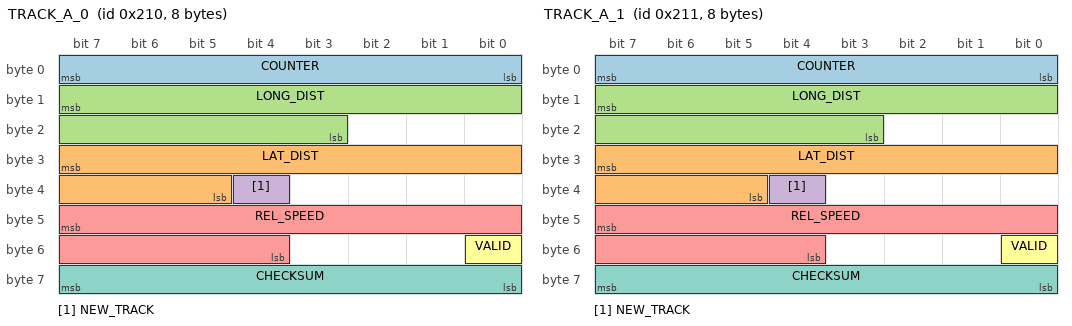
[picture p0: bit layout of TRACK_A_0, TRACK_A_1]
BO_ 528 TRACK_A_0: 8 XXX
 SG_ COUNTER : 7|8@0+ (1,0) [0|255] "" XXX
 SG_ LAT_DIST : 31|11@0- (0.04,0) [-50|50] "m" XXX
 SG_ LONG_DIST : 15|13@0+ (0.04,0) [0|300] "m" XXX
 SG_ NEW_TRACK : 36|1@0+ (1,0) [0|1] "" XXX
 SG_ REL_SPEED : 47|12@0- (0.025,0) [-100|100] "m/s" XXX
 SG_ VALID : 48|1@0+ (1,0) [0|1] "" XXX
 SG_ CHECKSUM : 63|8@0+ (1,0) [0|255] "" XXX

BO_ 529 TRACK_A_1: 8 XXX
 SG_ COUNTER : 7|8@0+ (1,0) [0|255] "" XXX
 SG_ LAT_DIST : 31|11@0- (0.04,0) [-50|50] "m" XXX
 SG_ LONG_DIST : 15|13@0+ (0.04,0) [0|300] "m" XXX
 SG_ NEW_TRACK : 36|1@0+ (1,0) [0|1] "" XXX
 SG_ REL_SPEED : 47|12@0- (0.025,0) [-100|100] "m/s" XXX
 SG_ VALID : 48|1@0+ (1,0) [0|1] "" XXX
 SG_ CHECKSUM : 63|8@0+ (1,0) [0|255] "" XXX

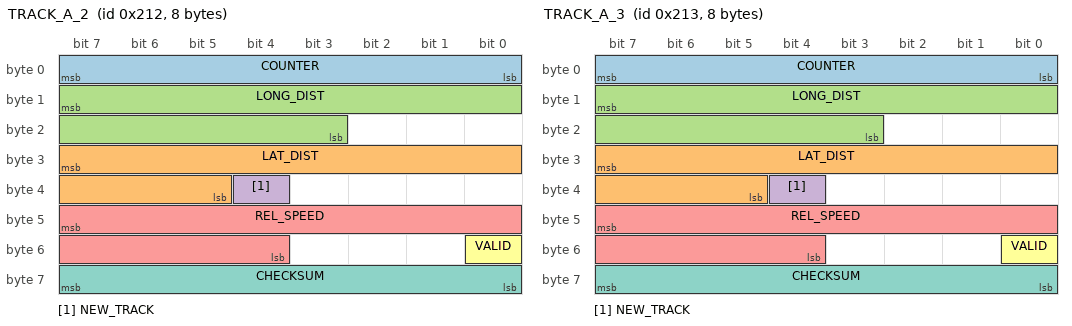
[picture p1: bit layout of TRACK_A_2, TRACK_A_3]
BO_ 530 TRACK_A_2: 8 XXX
 SG_ COUNTER : 7|8@0+ (1,0) [0|255] "" XXX
 SG_ LAT_DIST : 31|11@0- (0.04,0) [-50|50] "m" XXX
 SG_ LONG_DIST : 15|13@0+ (0.04,0) [0|300] "m" XXX
 SG_ NEW_TRACK : 36|1@0+ (1,0) [0|1] "" XXX
 SG_ REL_SPEED : 47|12@0- (0.025,0) [-100|100] "m/s" XXX
 SG_ VALID : 48|1@0+ (1,0) [0|1] "" XXX
 SG_ CHECKSUM : 63|8@0+ (1,0) [0|255] "" XXX

BO_ 531 TRACK_A_3: 8 XXX
 SG_ COUNTER : 7|8@0+ (1,0) [0|255] "" XXX
 SG_ LAT_DIST : 31|11@0- (0.04,0) [-50|50] "m" XXX
 SG_ LONG_DIST : 15|13@0+ (0.04,0) [0|300] "m" XXX
 SG_ NEW_TRACK : 36|1@0+ (1,0) [0|1] "" XXX
 SG_ REL_SPEED : 47|12@0- (0.025,0) [-100|100] "m/s" XXX
 SG_ VALID : 48|1@0+ (1,0) [0|1] "" XXX
 SG_ CHECKSUM : 63|8@0+ (1,0) [0|255] "" XXX

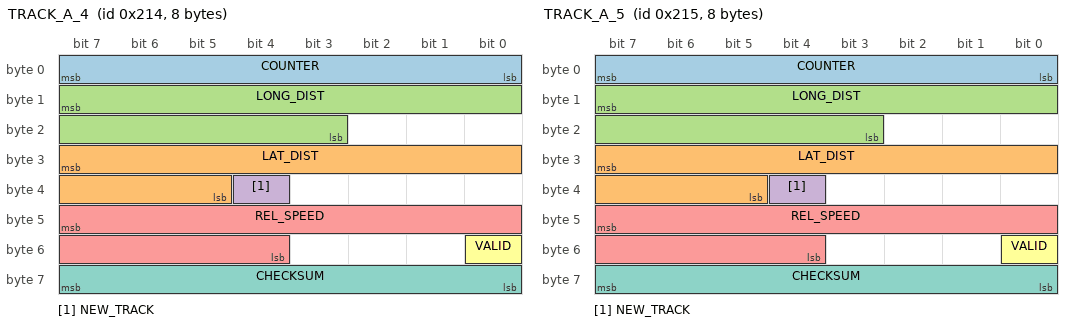
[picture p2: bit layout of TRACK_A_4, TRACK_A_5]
BO_ 532 TRACK_A_4: 8 XXX
 SG_ COUNTER : 7|8@0+ (1,0) [0|255] "" XXX
 SG_ LAT_DIST : 31|11@0- (0.04,0) [-50|50] "m" XXX
 SG_ LONG_DIST : 15|13@0+ (0.04,0) [0|300] "m" XXX
 SG_ NEW_TRACK : 36|1@0+ (1,0) [0|1] "" XXX
 SG_ REL_SPEED : 47|12@0- (0.025,0) [-100|100] "m/s" XXX
 SG_ VALID : 48|1@0+ (1,0) [0|1] "" XXX
 SG_ CHECKSUM : 63|8@0+ (1,0) [0|255] "" XXX

BO_ 533 TRACK_A_5: 8 XXX
 SG_ COUNTER : 7|8@0+ (1,0) [0|255] "" XXX
 SG_ LAT_DIST : 31|11@0- (0.04,0) [-50|50] "m" XXX
 SG_ LONG_DIST : 15|13@0+ (0.04,0) [0|300] "m" XXX
 SG_ NEW_TRACK : 36|1@0+ (1,0) [0|1] "" XXX
 SG_ REL_SPEED : 47|12@0- (0.025,0) [-100|100] "m/s" XXX
 SG_ VALID : 48|1@0+ (1,0) [0|1] "" XXX
 SG_ CHECKSUM : 63|8@0+ (1,0) [0|255] "" XXX

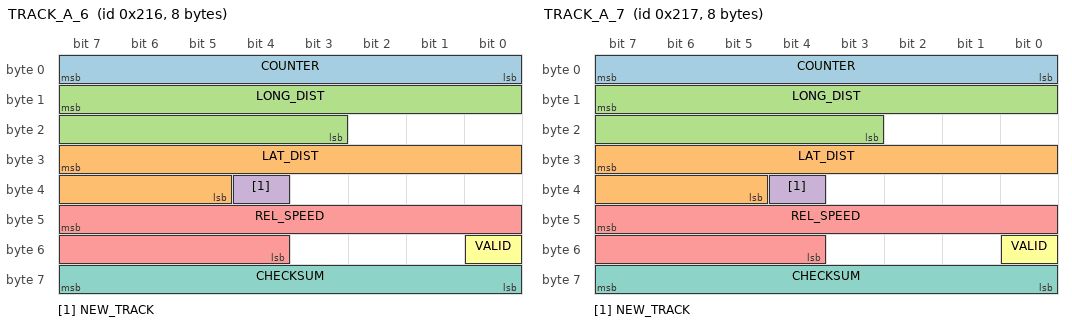
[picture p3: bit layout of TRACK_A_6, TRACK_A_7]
BO_ 534 TRACK_A_6: 8 XXX
 SG_ COUNTER : 7|8@0+ (1,0) [0|255] "" XXX
 SG_ LAT_DIST : 31|11@0- (0.04,0) [-50|50] "m" XXX
 SG_ LONG_DIST : 15|13@0+ (0.04,0) [0|300] "m" XXX
 SG_ NEW_TRACK : 36|1@0+ (1,0) [0|1] "" XXX
 SG_ REL_SPEED : 47|12@0- (0.025,0) [-100|100] "m/s" XXX
 SG_ VALID : 48|1@0+ (1,0) [0|1] "" XXX
 SG_ CHECKSUM : 63|8@0+ (1,0) [0|255] "" XXX

BO_ 535 TRACK_A_7: 8 XXX
 SG_ COUNTER : 7|8@0+ (1,0) [0|255] "" XXX
 SG_ LAT_DIST : 31|11@0- (0.04,0) [-50|50] "m" XXX
 SG_ LONG_DIST : 15|13@0+ (0.04,0) [0|300] "m" XXX
 SG_ NEW_TRACK : 36|1@0+ (1,0) [0|1] "" XXX
 SG_ REL_SPEED : 47|12@0- (0.025,0) [-100|100] "m/s" XXX
 SG_ VALID : 48|1@0+ (1,0) [0|1] "" XXX
 SG_ CHECKSUM : 63|8@0+ (1,0) [0|255] "" XXX

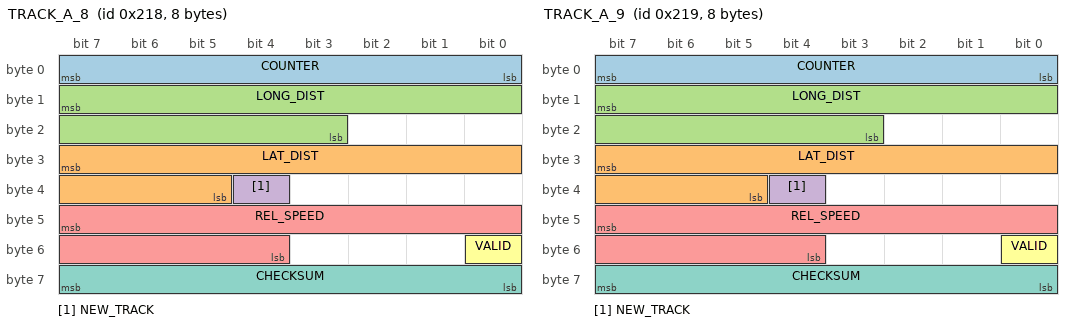
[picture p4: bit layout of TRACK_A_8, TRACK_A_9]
BO_ 536 TRACK_A_8: 8 XXX
 SG_ COUNTER : 7|8@0+ (1,0) [0|255] "" XXX
 SG_ LAT_DIST : 31|11@0- (0.04,0) [-50|50] "m" XXX
 SG_ LONG_DIST : 15|13@0+ (0.04,0) [0|300] "m" XXX
 SG_ NEW_TRACK : 36|1@0+ (1,0) [0|1] "" XXX
 SG_ REL_SPEED : 47|12@0- (0.025,0) [-100|100] "m/s" XXX
 SG_ VALID : 48|1@0+ (1,0) [0|1] "" XXX
 SG_ CHECKSUM : 63|8@0+ (1,0) [0|255] "" XXX

BO_ 537 TRACK_A_9: 8 XXX
 SG_ COUNTER : 7|8@0+ (1,0) [0|255] "" XXX
 SG_ LAT_DIST : 31|11@0- (0.04,0) [-50|50] "m" XXX
 SG_ LONG_DIST : 15|13@0+ (0.04,0) [0|300] "m" XXX
 SG_ NEW_TRACK : 36|1@0+ (1,0) [0|1] "" XXX
 SG_ REL_SPEED : 47|12@0- (0.025,0) [-100|100] "m/s" XXX
 SG_ VALID : 48|1@0+ (1,0) [0|1] "" XXX
 SG_ CHECKSUM : 63|8@0+ (1,0) [0|255] "" XXX

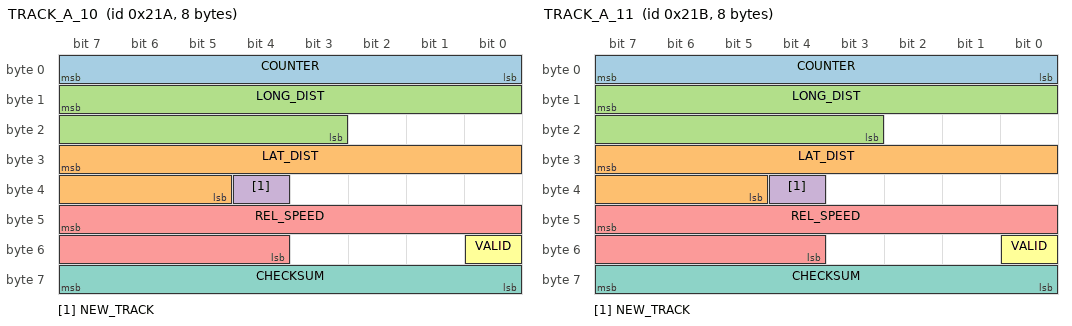
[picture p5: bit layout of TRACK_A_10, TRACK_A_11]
BO_ 538 TRACK_A_10: 8 XXX
 SG_ COUNTER : 7|8@0+ (1,0) [0|255] "" XXX
 SG_ LAT_DIST : 31|11@0- (0.04,0) [-50|50] "m" XXX
 SG_ LONG_DIST : 15|13@0+ (0.04,0) [0|300] "m" XXX
 SG_ NEW_TRACK : 36|1@0+ (1,0) [0|1] "" XXX
 SG_ REL_SPEED : 47|12@0- (0.025,0) [-100|100] "m/s" XXX
 SG_ VALID : 48|1@0+ (1,0) [0|1] "" XXX
 SG_ CHECKSUM : 63|8@0+ (1,0) [0|255] "" XXX

BO_ 539 TRACK_A_11: 8 XXX
 SG_ COUNTER : 7|8@0+ (1,0) [0|255] "" XXX
 SG_ LAT_DIST : 31|11@0- (0.04,0) [-50|50] "m" XXX
 SG_ LONG_DIST : 15|13@0+ (0.04,0) [0|300] "m" XXX
 SG_ NEW_TRACK : 36|1@0+ (1,0) [0|1] "" XXX
 SG_ REL_SPEED : 47|12@0- (0.025,0) [-100|100] "m/s" XXX
 SG_ VALID : 48|1@0+ (1,0) [0|1] "" XXX
 SG_ CHECKSUM : 63|8@0+ (1,0) [0|255] "" XXX

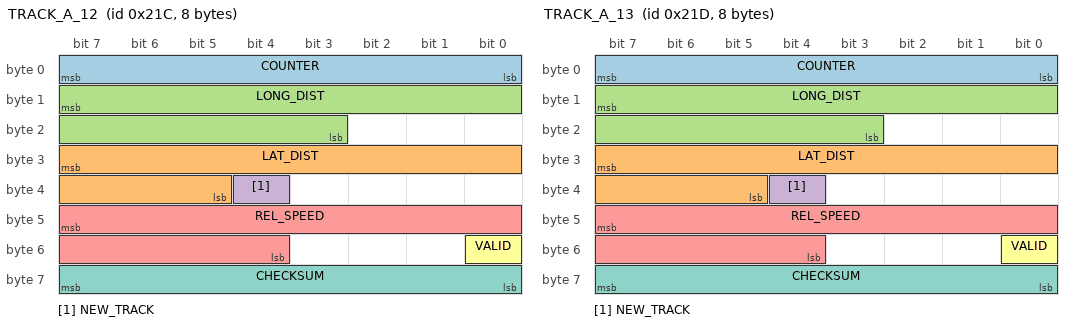
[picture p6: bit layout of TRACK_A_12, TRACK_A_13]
BO_ 540 TRACK_A_12: 8 XXX
 SG_ COUNTER : 7|8@0+ (1,0) [0|255] "" XXX
 SG_ LAT_DIST : 31|11@0- (0.04,0) [-50|50] "m" XXX
 SG_ LONG_DIST : 15|13@0+ (0.04,0) [0|300] "m" XXX
 SG_ NEW_TRACK : 36|1@0+ (1,0) [0|1] "" XXX
 SG_ REL_SPEED : 47|12@0- (0.025,0) [-100|100] "m/s" XXX
 SG_ VALID : 48|1@0+ (1,0) [0|1] "" XXX
 SG_ CHECKSUM : 63|8@0+ (1,0) [0|255] "" XXX

BO_ 541 TRACK_A_13: 8 XXX
 SG_ COUNTER : 7|8@0+ (1,0) [0|255] "" XXX
 SG_ LAT_DIST : 31|11@0- (0.04,0) [-50|50] "m" XXX
 SG_ LONG_DIST : 15|13@0+ (0.04,0) [0|300] "m" XXX
 SG_ NEW_TRACK : 36|1@0+ (1,0) [0|1] "" XXX
 SG_ REL_SPEED : 47|12@0- (0.025,0) [-100|100] "m/s" XXX
 SG_ VALID : 48|1@0+ (1,0) [0|1] "" XXX
 SG_ CHECKSUM : 63|8@0+ (1,0) [0|255] "" XXX

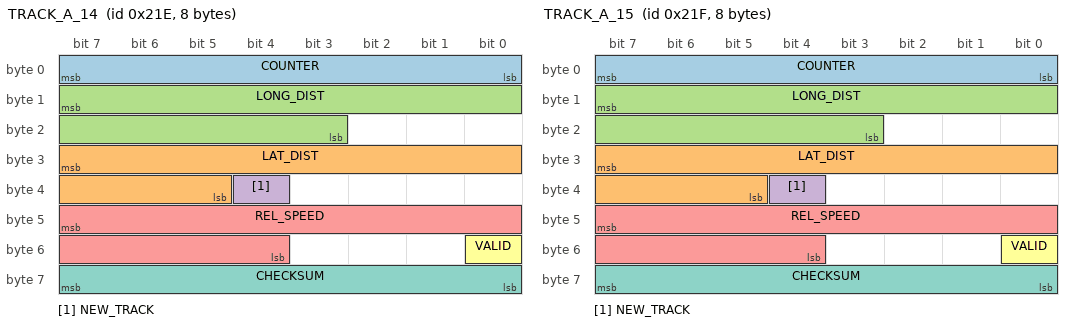
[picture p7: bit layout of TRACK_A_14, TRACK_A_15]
BO_ 542 TRACK_A_14: 8 XXX
 SG_ COUNTER : 7|8@0+ (1,0) [0|255] "" XXX
 SG_ LAT_DIST : 31|11@0- (0.04,0) [-50|50] "m" XXX
 SG_ LONG_DIST : 15|13@0+ (0.04,0) [0|300] "m" XXX
 SG_ NEW_TRACK : 36|1@0+ (1,0) [0|1] "" XXX
 SG_ REL_SPEED : 47|12@0- (0.025,0) [-100|100] "m/s" XXX
 SG_ VALID : 48|1@0+ (1,0) [0|1] "" XXX
 SG_ CHECKSUM : 63|8@0+ (1,0) [0|255] "" XXX

BO_ 543 TRACK_A_15: 8 XXX
 SG_ COUNTER : 7|8@0+ (1,0) [0|255] "" XXX
 SG_ LAT_DIST : 31|11@0- (0.04,0) [-50|50] "m" XXX
 SG_ LONG_DIST : 15|13@0+ (0.04,0) [0|300] "m" XXX
 SG_ NEW_TRACK : 36|1@0+ (1,0) [0|1] "" XXX
 SG_ REL_SPEED : 47|12@0- (0.025,0) [-100|100] "m/s" XXX
 SG_ VALID : 48|1@0+ (1,0) [0|1] "" XXX
 SG_ CHECKSUM : 63|8@0+ (1,0) [0|255] "" XXX

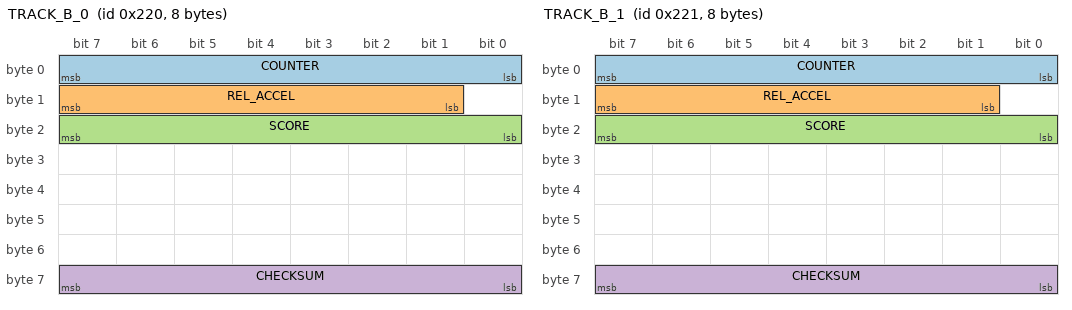
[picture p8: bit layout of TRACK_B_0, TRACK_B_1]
BO_ 544 TRACK_B_0: 8 XXX
 SG_ COUNTER : 7|8@0+ (1,0) [0|255] "" XXX
 SG_ REL_ACCEL : 15|7@0- (1,0) [-64|63] "" XXX
 SG_ SCORE : 23|8@0+ (1,0) [0|100] "" XXX
 SG_ CHECKSUM : 63|8@0+ (1,0) [0|255] "" XXX

BO_ 545 TRACK_B_1: 8 XXX
 SG_ COUNTER : 7|8@0+ (1,0) [0|255] "" XXX
 SG_ REL_ACCEL : 15|7@0- (1,0) [-64|63] "" XXX
 SG_ SCORE : 23|8@0+ (1,0) [0|100] "" XXX
 SG_ CHECKSUM : 63|8@0+ (1,0) [0|255] "" XXX

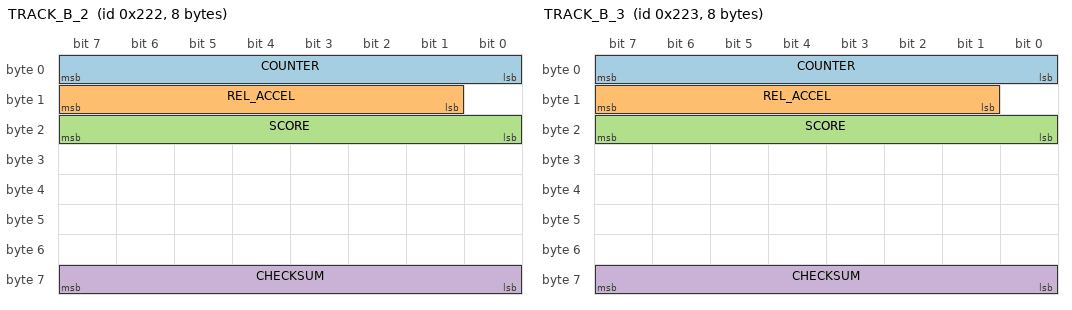
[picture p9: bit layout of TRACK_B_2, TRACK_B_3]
BO_ 546 TRACK_B_2: 8 XXX
 SG_ COUNTER : 7|8@0+ (1,0) [0|255] "" XXX
 SG_ REL_ACCEL : 15|7@0- (1,0) [-64|63] "" XXX
 SG_ SCORE : 23|8@0+ (1,0) [0|100] "" XXX
 SG_ CHECKSUM : 63|8@0+ (1,0) [0|255] "" XXX

BO_ 547 TRACK_B_3: 8 XXX
 SG_ COUNTER : 7|8@0+ (1,0) [0|255] "" XXX
 SG_ REL_ACCEL : 15|7@0- (1,0) [-64|63] "" XXX
 SG_ SCORE : 23|8@0+ (1,0) [0|100] "" XXX
 SG_ CHECKSUM : 63|8@0+ (1,0) [0|255] "" XXX

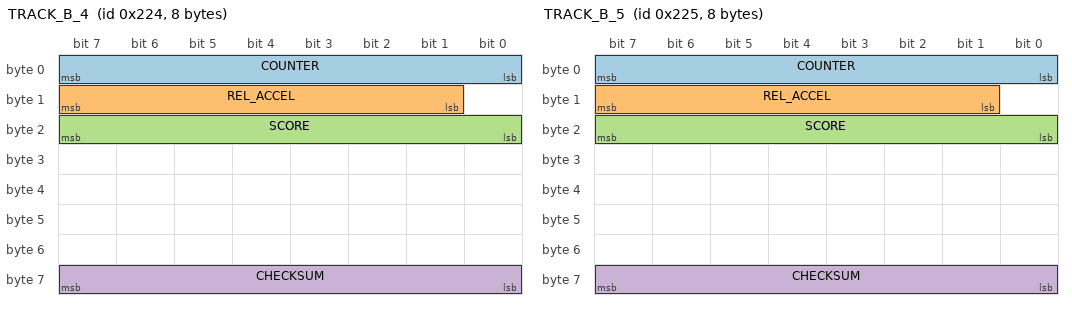
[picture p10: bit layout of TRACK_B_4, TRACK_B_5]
BO_ 548 TRACK_B_4: 8 XXX
 SG_ COUNTER : 7|8@0+ (1,0) [0|255] "" XXX
 SG_ REL_ACCEL : 15|7@0- (1,0) [-64|63] "" XXX
 SG_ SCORE : 23|8@0+ (1,0) [0|100] "" XXX
 SG_ CHECKSUM : 63|8@0+ (1,0) [0|255] "" XXX

BO_ 549 TRACK_B_5: 8 XXX
 SG_ COUNTER : 7|8@0+ (1,0) [0|255] "" XXX
 SG_ REL_ACCEL : 15|7@0- (1,0) [-64|63] "" XXX
 SG_ SCORE : 23|8@0+ (1,0) [0|100] "" XXX
 SG_ CHECKSUM : 63|8@0+ (1,0) [0|255] "" XXX

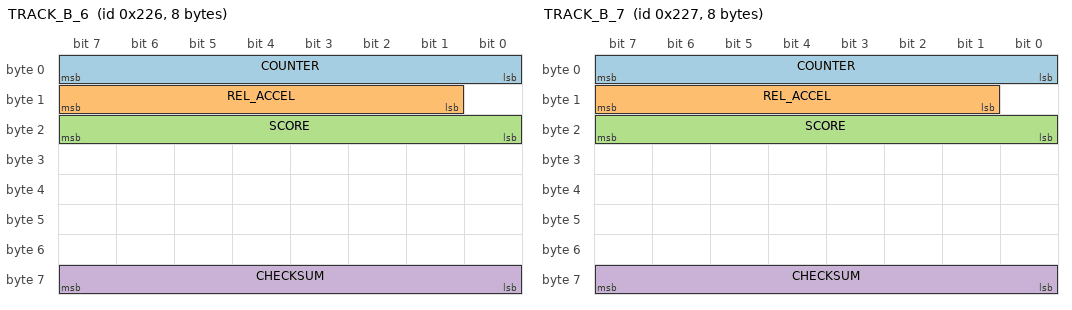
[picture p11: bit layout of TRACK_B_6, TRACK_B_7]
BO_ 550 TRACK_B_6: 8 XXX
 SG_ COUNTER : 7|8@0+ (1,0) [0|255] "" XXX
 SG_ REL_ACCEL : 15|7@0- (1,0) [-64|63] "" XXX
 SG_ SCORE : 23|8@0+ (1,0) [0|100] "" XXX
 SG_ CHECKSUM : 63|8@0+ (1,0) [0|255] "" XXX

BO_ 551 TRACK_B_7: 8 XXX
 SG_ COUNTER : 7|8@0+ (1,0) [0|255] "" XXX
 SG_ REL_ACCEL : 15|7@0- (1,0) [-64|63] "" XXX
 SG_ SCORE : 23|8@0+ (1,0) [0|100] "" XXX
 SG_ CHECKSUM : 63|8@0+ (1,0) [0|255] "" XXX

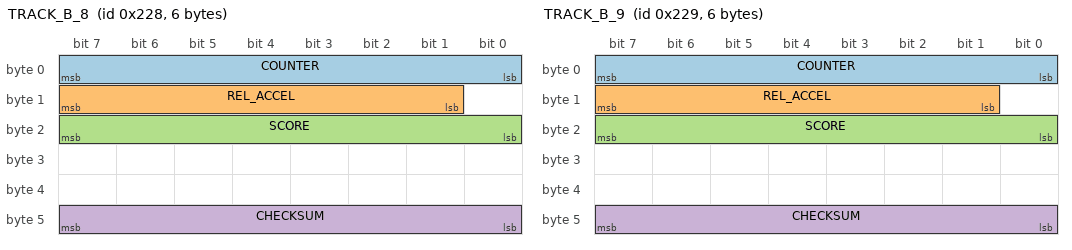
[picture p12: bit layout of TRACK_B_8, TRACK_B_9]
BO_ 552 TRACK_B_8: 6 XXX
 SG_ COUNTER : 7|8@0+ (1,0) [0|255] "" XXX
 SG_ REL_ACCEL : 15|7@0- (1,0) [-64|63] "" XXX
 SG_ SCORE : 23|8@0+ (1,0) [0|100] "" XXX
 SG_ CHECKSUM : 47|8@0+ (1,0) [0|255] "" XXX

BO_ 553 TRACK_B_9: 6 XXX
 SG_ COUNTER : 7|8@0+ (1,0) [0|255] "" XXX
 SG_ REL_ACCEL : 15|7@0- (1,0) [-64|63] "" XXX
 SG_ SCORE : 23|8@0+ (1,0) [0|100] "" XXX
 SG_ CHECKSUM : 47|8@0+ (1,0) [0|255] "" XXX

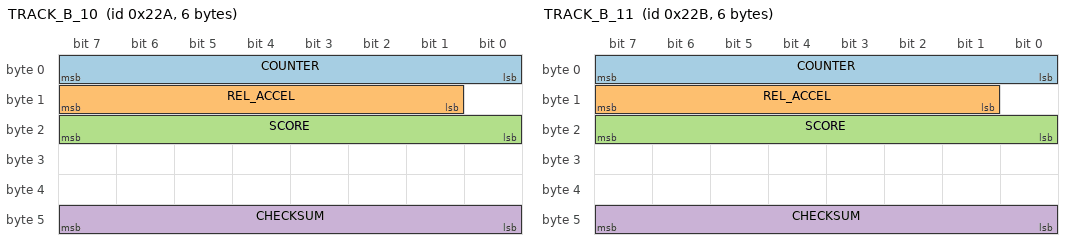
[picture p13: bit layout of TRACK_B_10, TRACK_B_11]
BO_ 554 TRACK_B_10: 6 XXX
 SG_ COUNTER : 7|8@0+ (1,0) [0|255] "" XXX
 SG_ REL_ACCEL : 15|7@0- (1,0) [-64|63] "" XXX
 SG_ SCORE : 23|8@0+ (1,0) [0|100] "" XXX
 SG_ CHECKSUM : 47|8@0+ (1,0) [0|255] "" XXX

BO_ 555 TRACK_B_11: 6 XXX
 SG_ COUNTER : 7|8@0+ (1,0) [0|255] "" XXX
 SG_ REL_ACCEL : 15|7@0- (1,0) [-64|63] "" XXX
 SG_ SCORE : 23|8@0+ (1,0) [0|100] "" XXX
 SG_ CHECKSUM : 47|8@0+ (1,0) [0|255] "" XXX

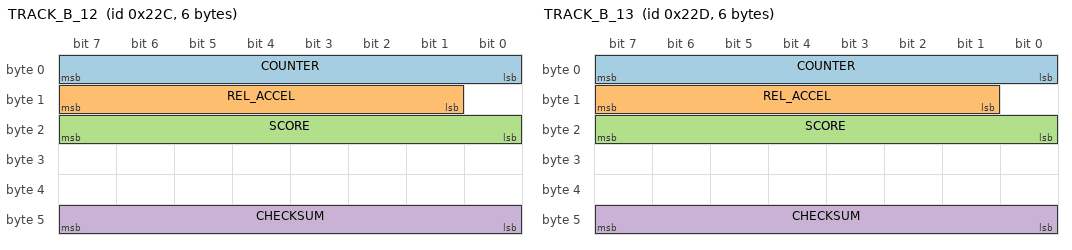
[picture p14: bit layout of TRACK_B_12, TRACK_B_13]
BO_ 556 TRACK_B_12: 6 XXX
 SG_ COUNTER : 7|8@0+ (1,0) [0|255] "" XXX
 SG_ REL_ACCEL : 15|7@0- (1,0) [-64|63] "" XXX
 SG_ SCORE : 23|8@0+ (1,0) [0|100] "" XXX
 SG_ CHECKSUM : 47|8@0+ (1,0) [0|255] "" XXX

BO_ 557 TRACK_B_13: 6 XXX
 SG_ COUNTER : 7|8@0+ (1,0) [0|255] "" XXX
 SG_ REL_ACCEL : 15|7@0- (1,0) [-64|63] "" XXX
 SG_ SCORE : 23|8@0+ (1,0) [0|100] "" XXX
 SG_ CHECKSUM : 47|8@0+ (1,0) [0|255] "" XXX

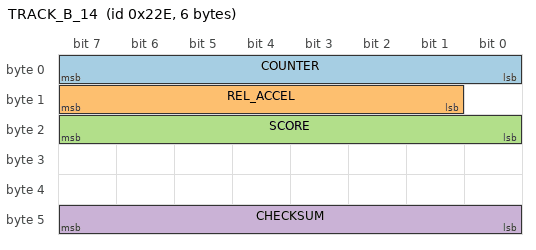
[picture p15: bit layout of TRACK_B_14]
BO_ 558 TRACK_B_14: 6 XXX
 SG_ COUNTER : 7|8@0+ (1,0) [0|255] "" XXX
 SG_ REL_ACCEL : 15|7@0- (1,0) [-64|63] "" XXX
 SG_ SCORE : 23|8@0+ (1,0) [0|100] "" XXX
 SG_ CHECKSUM : 47|8@0+ (1,0) [0|255] "" XXX

BU_: XXX DSU HCU EPS IPAS

VAL_ 513 STATE 5 "FAULT_TIMEOUT" 4 "FAULT_STARTUP" 3 "FAULT_SCE" 2 "FAULT_SEND" 1 "FAULT_BAD_CHECKSUM" 0 "NO_FAULT" ;

VAL_ 780 CRUISE_SPEED 255 "no_speed" 252 "stopped";
VAL_ 780 HUD_LEAD 3 "acc_off" 2 "solid_car" 1 "dashed_car" 0 "no_car";
VAL_ 884 DASHBOARD_ALERT 0 "none" 51 "acc_problem" 55 "cmbs_problem" 75 "key_not_detected" 79 "fasten_seatbelt" 111 "lkas_problem" 131 "brake_system_problem" 132 "brake_hold_problem" 139 "tbd" 161 "door_open";
VAL_ 891 WIPERS 4 "High" 2 "Low" 0 "Off";

VAL_ 506 FCW 3 "fcw" 2 "fcw" 1 "fcw" 0 "no_fcw";
VAL_ 506 CHIME 4 "double_chime" 3 "single_chime" 2 "continuous_chime" 1 "repeating_chime" 0 "no_chime";
VAL_ 506 AEB_STATUS 3 "aeb_prepare" 2 "aeb_ready" 1 "aeb_braking" 0 "no_aeb";
VAL_ 829 BEEP 3 "single_beep" 2 "triple_beep" 1 "repeated_beep" 0 "no_beep";

VAL_ 399 STEER_STATUS 6 "tmp_fault" 5 "fault_1" 4 "no_torque_alert_2" 3 "low_speed_lockout" 2 "no_torque_alert_1" 0 "normal" ;
VAL_ 419 GEAR_SHIFTER 10 "S" 4 "D" 3 "N" 2 "R" 1 "P" ;
VAL_ 422 CRUISE_BUTTONS 7 "tbd" 6 "tbd" 5 "tbd" 4 "accel_res" 3 "decel_set" 2 "cancel" 1 "main" 0 "none" ;
VAL_ 422 LIGHTS_SETTING 3 "high_beam" 2 "low_beam" 1 "position" 0 "no_lights" ;
